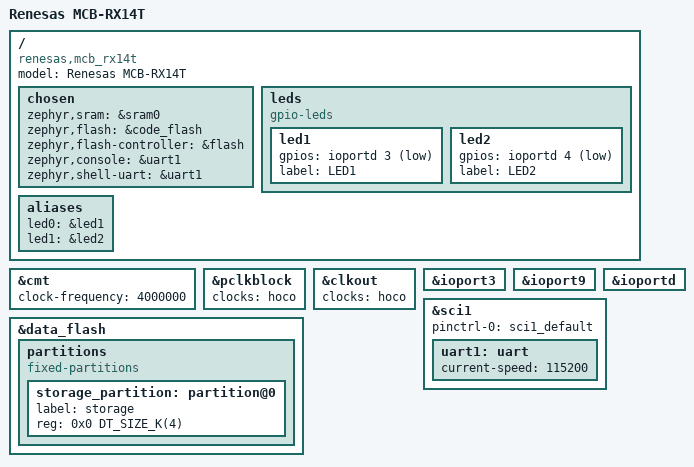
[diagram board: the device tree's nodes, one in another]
/*
 * Copyright (c) 2026 Renesas Electronics Corporation
 *
 * SPDX-License-Identifier: Apache-2.0
 */

/dts-v1/;

#include <renesas/r5f514t5amfm.dtsi>
#include <zephyr/dt-bindings/gpio/gpio.h>
#include "mcb_rx14t-pinctrl.dtsi"

/ {
	model = "Renesas MCB-RX14T";
	compatible = "renesas,mcb_rx14t";

	chosen {
		zephyr,sram = &sram0;
		zephyr,flash = &code_flash;
		zephyr,flash-controller = &flash;
		zephyr,console = &uart1;
		zephyr,shell-uart = &uart1;
	};

	leds {
		compatible = "gpio-leds";

		led1: led1 {
			gpios = <&ioportd 3 GPIO_ACTIVE_LOW>;
			label = "LED1";
		};

		led2: led2 {
			gpios = <&ioportd 4 GPIO_ACTIVE_LOW>;
			label = "LED2";
		};
	};

	aliases {
		led0 = &led1;
		led1 = &led2;
	};
};

&cmt {
	clock-frequency = <4000000>;
	status = "okay";
};

&pclkblock {
	clocks = <&hoco>;
};

&clkout {
	clocks = <&hoco>;
};

&ioport3 {
	status = "okay";
};

&ioport9 {
	status = "okay";
};

&ioportd {
	status = "okay";
};

&sci1 {
	pinctrl-0 = <&sci1_default>;
	pinctrl-names = "default";
	status = "okay";

	uart1: uart {
		current-speed = <115200>;
		status = "okay";
	};
};

&data_flash {
	partitions {
		compatible = "fixed-partitions";
		#address-cells = <1>;
		#size-cells = <1>;

		storage_partition: partition@0 {
			label = "storage";
			reg = <0x0 DT_SIZE_K(4)>;
		};
	};
};
